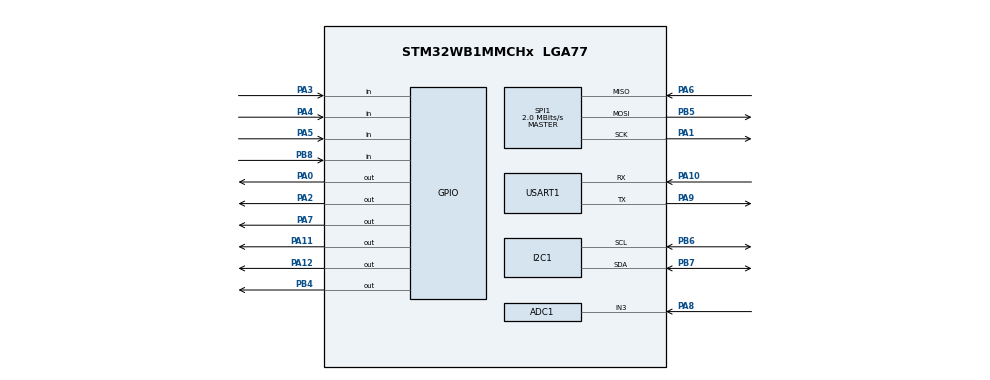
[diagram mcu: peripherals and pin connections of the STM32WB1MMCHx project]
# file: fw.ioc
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ADC1.Channel-0\#ChannelRegularConversion=ADC_CHANNEL_3
ADC1.NbrOfConversionFlag=1
ADC1.Rank-0\#ChannelRegularConversion=1
ADC1.SamplingTime-0\#ChannelRegularConversion=ADC_SAMPLINGTIME_COMMON_1
ADC1.SelectedChannel=ADC_CHANNEL_3
ADC1.master=1
I2C1.Timing=0x00100D14
Mcu.Family=STM32WB
Mcu.Name=STM32WB1MMCHx
Mcu.Package=LGA77
NVIC.PriorityGroup=NVIC_PRIORITYGROUP_4
PA0.Signal=GPIO_Output
PA1.Mode=Full_Duplex_Master
PA1.Signal=SPI1_SCK
PA10.Mode=Asynchronous
PA10.Signal=USART1_RX
PA11.Signal=GPIO_Output
PA12.Signal=GPIO_Output
PA13.Mode=Serial_Wire
PA13.Signal=SYS_JTMS-SWDIO
PA14.Mode=Serial_Wire
PA14.Signal=SYS_JTCK-SWCLK
PA2.Signal=GPIO_Output
PA3.Signal=GPIO_Input
PA4.Signal=GPIO_Input
PA5.Signal=GPIO_Input
PA6.Mode=Full_Duplex_Master
PA6.Signal=SPI1_MISO
PA7.Signal=GPIO_Output
PA8.Signal=ADCx_IN3
PA9.Mode=Asynchronous
PA9.Signal=USART1_TX
PB4.Signal=GPIO_Output
PB5.Mode=Full_Duplex_Master
PB5.Signal=SPI1_MOSI
PB6.Mode=I2C
PB6.Signal=I2C1_SCL
PB7.Mode=I2C
PB7.Signal=I2C1_SDA
PB8.Signal=GPIO_Input
ProjectManager.HeapSize=0x200
ProjectManager.StackSize=0x400
ProjectManager.TargetToolchain=STM32CubeIDE
RCC.APB3Freq_Value=16000000
RCC.HSE_VALUE=32000000
RCC.HSI_VALUE=16000000
RCC.LSE_VALUE=32768
RCC.VCOOutputFreq_Value=32000000
SH.ADCx_IN3.0=ADC1_IN3,IN3-Single-Ended
SPI1.CalculateBaudRate=2.0 MBits/s
SPI1.Direction=SPI_DIRECTION_2LINES
SPI1.Mode=SPI_MODE_MASTER
SPI1.VirtualType=VM_MASTER
USART1.VirtualMode-Asynchronous=VM_ASYNC
VP_MEMORYMAP_VS_MEMORYMAP.Mode=CurAppReg
board=custom

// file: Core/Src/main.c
/* USER CODE BEGIN Header */
/**
  ******************************************************************************
  * @file           : main.c
  * @brief          : Main program body
  ******************************************************************************
  * @attention
  *
  * Copyright (c) 2025 STMicroelectronics.
  * All rights reserved.
  *
  * This software is licensed under terms that can be found in the LICENSE file
  * in the root directory of this software component.
  * If no LICENSE file comes with this software, it is provided AS-IS.
  *
  ******************************************************************************
  */
/* USER CODE END Header */
#include "main.h"

/* USER CODE BEGIN Includes */
#include <stdio.h>
/* USER CODE END Includes */

ADC_HandleTypeDef hadc1;

I2C_HandleTypeDef hi2c1;

SPI_HandleTypeDef hspi1;

UART_HandleTypeDef huart1;

void SystemClock_Config(void);
void PeriphCommonClock_Config(void);
static void MX_GPIO_Init(void);
static void MX_ADC1_Init(void);
static void MX_I2C1_Init(void);
static void MX_SPI1_Init(void);
static void MX_USART1_UART_Init(void);

int main(void)
{

  /* MCU Configuration--------------------------------------------------------*/

  /* Reset of all peripherals, Initializes the Flash interface and the Systick. */
  HAL_Init();

  /* Configure the system clock */
  SystemClock_Config();

  /* Configure the peripherals common clocks */
  PeriphCommonClock_Config();

  /* Initialize all configured peripherals */
  MX_GPIO_Init();
  MX_ADC1_Init();
  MX_I2C1_Init();
  MX_SPI1_Init();
  MX_USART1_UART_Init();
  /* USER CODE BEGIN 2 */
  uint8_t buffer[30];
  int len = sprintf((char*)buffer, "Hello World, BAGEL here\r\n");
  HAL_UART_Transmit(&huart1, buffer, len, 1000);

  uint8_t start_msg[] = "I2C Scanning:\r\n";
  uint8_t end_msg[] = "Done\r\n";

  HAL_GPIO_WritePin(GPIOA, GPIO_PIN_2, GPIO_PIN_SET);

  /* USER CODE END 2 */

  /* Infinite loop */
  while (1)
  {

    /* USER CODE BEGIN 3 */

	  HAL_UART_Transmit(&huart1, start_msg, sizeof(start_msg), 1000);

	  for (int i=0; i<128;i++){
		  if (HAL_I2C_IsDeviceReady(&hi2c1, (uint16_t)(i<<1), 3, 5) == HAL_OK){
			  len = sprintf((char*)buffer, "Detected 0x%X\r\n", i);
			  HAL_UART_Transmit(&huart1, buffer, len, 1000);
		  }
	  }

	  HAL_UART_Transmit(&huart1, end_msg, sizeof(end_msg), 1000);

	  HAL_Delay(5000);

  }
  /* USER CODE END 3 */
}

void SystemClock_Config(void)
{
  RCC_OscInitTypeDef RCC_OscInitStruct = {0};
  RCC_ClkInitTypeDef RCC_ClkInitStruct = {0};

  /** Initializes the RCC Oscillators according to the specified parameters
  * in the RCC_OscInitTypeDef structure.
  */
  RCC_OscInitStruct.OscillatorType = RCC_OSCILLATORTYPE_HSI|RCC_OSCILLATORTYPE_MSI;
  RCC_OscInitStruct.HSIState = RCC_HSI_ON;
  RCC_OscInitStruct.MSIState = RCC_MSI_ON;
  RCC_OscInitStruct.HSICalibrationValue = RCC_HSICALIBRATION_DEFAULT;
  RCC_OscInitStruct.MSICalibrationValue = RCC_MSICALIBRATION_DEFAULT;
  RCC_OscInitStruct.MSIClockRange = RCC_MSIRANGE_6;
  RCC_OscInitStruct.PLL.PLLState = RCC_PLL_NONE;
  if (HAL_RCC_OscConfig(&RCC_OscInitStruct) != HAL_OK)
  {
    Error_Handler();
  }

  /** Configure the SYSCLKSource, HCLK, PCLK1 and PCLK2 clocks dividers
  */
  RCC_ClkInitStruct.ClockType = RCC_CLOCKTYPE_HCLK4|RCC_CLOCKTYPE_HCLK2
                              |RCC_CLOCKTYPE_HCLK|RCC_CLOCKTYPE_SYSCLK
                              |RCC_CLOCKTYPE_PCLK1|RCC_CLOCKTYPE_PCLK2;
  RCC_ClkInitStruct.SYSCLKSource = RCC_SYSCLKSOURCE_MSI;
  RCC_ClkInitStruct.AHBCLKDivider = RCC_SYSCLK_DIV1;
  RCC_ClkInitStruct.APB1CLKDivider = RCC_HCLK_DIV1;
  RCC_ClkInitStruct.APB2CLKDivider = RCC_HCLK_DIV1;
  RCC_ClkInitStruct.AHBCLK2Divider = RCC_SYSCLK_DIV1;
  RCC_ClkInitStruct.AHBCLK4Divider = RCC_SYSCLK_DIV1;

  if (HAL_RCC_ClockConfig(&RCC_ClkInitStruct, FLASH_LATENCY_0) != HAL_OK)
  {
    Error_Handler();
  }
}

void PeriphCommonClock_Config(void)
{
  RCC_PeriphCLKInitTypeDef PeriphClkInitStruct = {0};

  /** Initializes the peripherals clock
  */
  PeriphClkInitStruct.PeriphClockSelection = RCC_PERIPHCLK_SMPS;
  PeriphClkInitStruct.SmpsClockSelection = RCC_SMPSCLKSOURCE_HSI;
  PeriphClkInitStruct.SmpsDivSelection = RCC_SMPSCLKDIV_RANGE1;

  if (HAL_RCCEx_PeriphCLKConfig(&PeriphClkInitStruct) != HAL_OK)
  {
    Error_Handler();
  }
}

static void MX_ADC1_Init(void)
{

  ADC_ChannelConfTypeDef sConfig = {0};

  /** Common config
  */
  hadc1.Instance = ADC1;
  hadc1.Init.ClockPrescaler = ADC_CLOCK_ASYNC_DIV1;
  hadc1.Init.Resolution = ADC_RESOLUTION_12B;
  hadc1.Init.DataAlign = ADC_DATAALIGN_RIGHT;
  hadc1.Init.ScanConvMode = ADC_SCAN_DISABLE;
  hadc1.Init.EOCSelection = ADC_EOC_SINGLE_CONV;
  hadc1.Init.SamplingTimeCommon1 = ADC_SAMPLETIME_1CYCLE_5;
  hadc1.Init.SamplingTimeCommon2 = ADC_SAMPLETIME_1CYCLE_5;
  hadc1.Init.LowPowerAutoWait = DISABLE;
  hadc1.Init.ContinuousConvMode = DISABLE;
  hadc1.Init.NbrOfConversion = 1;
  hadc1.Init.DiscontinuousConvMode = DISABLE;
  hadc1.Init.ExternalTrigConv = ADC_SOFTWARE_START;
  hadc1.Init.ExternalTrigConvEdge = ADC_EXTERNALTRIGCONVEDGE_NONE;
  hadc1.Init.DMAContinuousRequests = DISABLE;
  hadc1.Init.Overrun = ADC_OVR_DATA_PRESERVED;
  if (HAL_ADC_Init(&hadc1) != HAL_OK)
  {
    Error_Handler();
  }

  /** Configure Regular Channel
  */
  sConfig.Channel = ADC_CHANNEL_3;
  sConfig.Rank = ADC_REGULAR_RANK_1;
  sConfig.SamplingTime = ADC_SAMPLINGTIME_COMMON_1;
  if (HAL_ADC_ConfigChannel(&hadc1, &sConfig) != HAL_OK)
  {
    Error_Handler();
  }

}

static void MX_I2C1_Init(void)
{

  hi2c1.Instance = I2C1;
  hi2c1.Init.Timing = 0x00100D14;
  hi2c1.Init.OwnAddress1 = 0;
  hi2c1.Init.AddressingMode = I2C_ADDRESSINGMODE_7BIT;
  hi2c1.Init.DualAddressMode = I2C_DUALADDRESS_DISABLE;
  hi2c1.Init.OwnAddress2 = 0;
  hi2c1.Init.OwnAddress2Masks = I2C_OA2_NOMASK;
  hi2c1.Init.GeneralCallMode = I2C_GENERALCALL_DISABLE;
  hi2c1.Init.NoStretchMode = I2C_NOSTRETCH_DISABLE;
  if (HAL_I2C_Init(&hi2c1) != HAL_OK)
  {
    Error_Handler();
  }

  /** Configure Analogue filter
  */
  if (HAL_I2CEx_ConfigAnalogFilter(&hi2c1, I2C_ANALOGFILTER_ENABLE) != HAL_OK)
  {
    Error_Handler();
  }

  /** Configure Digital filter
  */
  if (HAL_I2CEx_ConfigDigitalFilter(&hi2c1, 0) != HAL_OK)
  {
    Error_Handler();
  }

}

static void MX_SPI1_Init(void)
{

  /* SPI1 parameter configuration*/
  hspi1.Instance = SPI1;
  hspi1.Init.Mode = SPI_MODE_MASTER;
  hspi1.Init.Direction = SPI_DIRECTION_2LINES;
  hspi1.Init.DataSize = SPI_DATASIZE_8BIT;
  hspi1.Init.CLKPolarity = SPI_POLARITY_LOW;
  hspi1.Init.CLKPhase = SPI_PHASE_1EDGE;
  hspi1.Init.NSS = SPI_NSS_SOFT;
  hspi1.Init.BaudRatePrescaler = SPI_BAUDRATEPRESCALER_2;
  hspi1.Init.FirstBit = SPI_FIRSTBIT_MSB;
  hspi1.Init.TIMode = SPI_TIMODE_DISABLE;
  hspi1.Init.CRCCalculation = SPI_CRCCALCULATION_DISABLE;
  hspi1.Init.CRCPolynomial = 7;
  hspi1.Init.CRCLength = SPI_CRC_LENGTH_DATASIZE;
  hspi1.Init.NSSPMode = SPI_NSS_PULSE_ENABLE;
  if (HAL_SPI_Init(&hspi1) != HAL_OK)
  {
    Error_Handler();
  }

}

static void MX_USART1_UART_Init(void)
{

  huart1.Instance = USART1;
  huart1.Init.BaudRate = 115200;
  huart1.Init.WordLength = UART_WORDLENGTH_8B;
  huart1.Init.StopBits = UART_STOPBITS_1;
  huart1.Init.Parity = UART_PARITY_NONE;
  huart1.Init.Mode = UART_MODE_TX_RX;
  huart1.Init.HwFlowCtl = UART_HWCONTROL_NONE;
  huart1.Init.OverSampling = UART_OVERSAMPLING_16;
  huart1.Init.OneBitSampling = UART_ONE_BIT_SAMPLE_DISABLE;
  huart1.Init.ClockPrescaler = UART_PRESCALER_DIV1;
  huart1.AdvancedInit.AdvFeatureInit = UART_ADVFEATURE_NO_INIT;
  if (HAL_UART_Init(&huart1) != HAL_OK)
  {
    Error_Handler();
  }
  if (HAL_UARTEx_SetTxFifoThreshold(&huart1, UART_TXFIFO_THRESHOLD_1_8) != HAL_OK)
  {
    Error_Handler();
  }
  if (HAL_UARTEx_SetRxFifoThreshold(&huart1, UART_RXFIFO_THRESHOLD_1_8) != HAL_OK)
  {
    Error_Handler();
  }
  if (HAL_UARTEx_DisableFifoMode(&huart1) != HAL_OK)
  {
    Error_Handler();
  }

}

static void MX_GPIO_Init(void)
{
  GPIO_InitTypeDef GPIO_InitStruct = {0};

  /* GPIO Ports Clock Enable */
  __HAL_RCC_GPIOA_CLK_ENABLE();
  __HAL_RCC_GPIOB_CLK_ENABLE();

  /*Configure GPIO pin Output Level */
  HAL_GPIO_WritePin(GPIOA, GPIO_PIN_2|GPIO_PIN_7|GPIO_PIN_12|GPIO_PIN_11
                          |GPIO_PIN_0, GPIO_PIN_RESET);

  /*Configure GPIO pin Output Level */
  HAL_GPIO_WritePin(GPIOB, GPIO_PIN_4, GPIO_PIN_RESET);

  /*Configure GPIO pins : PA4 PA3 PA5 */
  GPIO_InitStruct.Pin = GPIO_PIN_4|GPIO_PIN_3|GPIO_PIN_5;
  GPIO_InitStruct.Mode = GPIO_MODE_INPUT;
  GPIO_InitStruct.Pull = GPIO_NOPULL;
  HAL_GPIO_Init(GPIOA, &GPIO_InitStruct);

  /*Configure GPIO pins : PA2 PA7 PA12 PA11
                           PA0 */
  GPIO_InitStruct.Pin = GPIO_PIN_2|GPIO_PIN_7|GPIO_PIN_12|GPIO_PIN_11
                          |GPIO_PIN_0;
  GPIO_InitStruct.Mode = GPIO_MODE_OUTPUT_PP;
  GPIO_InitStruct.Pull = GPIO_NOPULL;
  GPIO_InitStruct.Speed = GPIO_SPEED_FREQ_LOW;
  HAL_GPIO_Init(GPIOA, &GPIO_InitStruct);

  /*Configure GPIO pin : PB8 */
  GPIO_InitStruct.Pin = GPIO_PIN_8;
  GPIO_InitStruct.Mode = GPIO_MODE_INPUT;
  GPIO_InitStruct.Pull = GPIO_NOPULL;
  HAL_GPIO_Init(GPIOB, &GPIO_InitStruct);

  /*Configure GPIO pin : PB4 */
  GPIO_InitStruct.Pin = GPIO_PIN_4;
  GPIO_InitStruct.Mode = GPIO_MODE_OUTPUT_PP;
  GPIO_InitStruct.Pull = GPIO_NOPULL;
  GPIO_InitStruct.Speed = GPIO_SPEED_FREQ_LOW;
  HAL_GPIO_Init(GPIOB, &GPIO_InitStruct);

}

void Error_Handler(void)
{
  __disable_irq();
  while (1)
  {
  }
}
